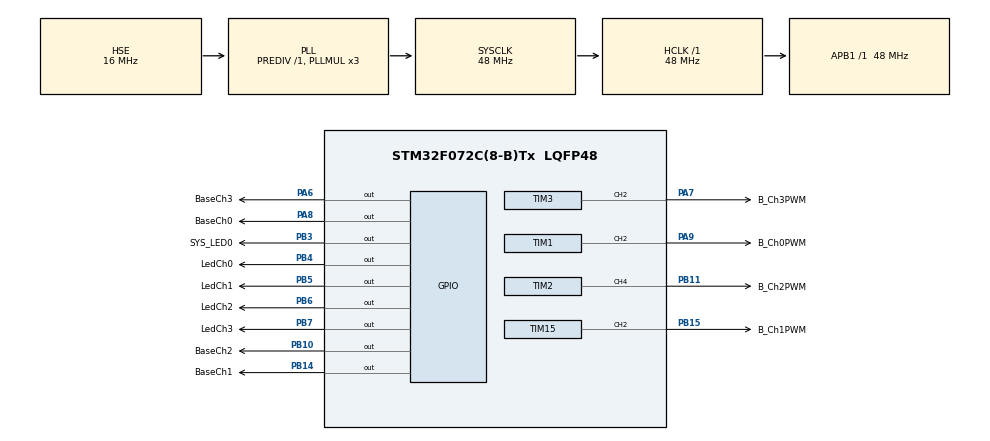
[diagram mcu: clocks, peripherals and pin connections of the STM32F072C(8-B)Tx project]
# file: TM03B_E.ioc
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Mcu.Family=STM32F0
Mcu.Name=STM32F072C(8-B)Tx
Mcu.Package=LQFP48
NVIC.TIM15_IRQn=true\:0\:0\:false\:false\:true\:true
NVIC.TIM1_BRK_UP_TRG_COM_IRQn=true\:0\:0\:false\:false\:true\:true
NVIC.TIM1_CC_IRQn=true\:0\:0\:false\:false\:true\:true
NVIC.TIM2_IRQn=true\:0\:0\:false\:false\:true\:true
NVIC.TIM3_IRQn=true\:0\:0\:false\:false\:true\:true
NVIC.TIM7_IRQn=true\:1\:0\:true\:false\:true\:true
PA13.Mode=Serial_Wire
PA13.Signal=SYS_SWDIO
PA14.Mode=Serial_Wire
PA14.Signal=SYS_SWCLK
PA6.GPIO_Label=BaseCh3
PA6.Signal=GPIO_Output
PA7.GPIO_Label=B_Ch3PWM
PA7.Signal=S_TIM3_CH2
PA8.GPIO_Label=BaseCh0
PA8.Signal=GPIO_Output
PA9.GPIO_Label=B_Ch0PWM
PA9.Signal=S_TIM1_CH2
PB10.GPIO_Label=BaseCh2
PB10.Signal=GPIO_Output
PB11.GPIO_Label=B_Ch2PWM
PB11.Signal=S_TIM2_CH4
PB14.GPIO_Label=BaseCh1
PB14.Signal=GPIO_Output
PB15.GPIO_Label=B_Ch1PWM
PB15.Signal=S_TIM15_CH2
PB3.GPIO_Label=SYS_LED0
PB3.Signal=GPIO_Output
PB4.GPIO_Label=LedCh0
PB4.PinState=GPIO_PIN_SET
PB4.Signal=GPIO_Output
PB5.GPIO_Label=LedCh1
PB5.PinState=GPIO_PIN_SET
PB5.Signal=GPIO_Output
PB6.GPIO_Label=LedCh2
PB6.PinState=GPIO_PIN_SET
PB6.Signal=GPIO_Output
PB7.GPIO_Label=LedCh3
PB7.PinState=GPIO_PIN_SET
PB7.Signal=GPIO_Output
PF0-OSC_IN.Mode=HSE-External-Oscillator
PF0-OSC_IN.Signal=RCC_OSC_IN
PF1-OSC_OUT.Mode=HSE-External-Oscillator
PF1-OSC_OUT.Signal=RCC_OSC_OUT
ProjectManager.HeapSize=0x200
ProjectManager.StackSize=0x400
ProjectManager.TargetToolchain=MDK-ARM V5
RCC.AHBFreq_Value=48000000
RCC.APB1Freq_Value=48000000
RCC.APB1TimFreq_Value=48000000
RCC.HCLKFreq_Value=48000000
RCC.HSE_VALUE=16000000
RCC.PLLMUL=RCC_PLL_MUL3
RCC.PLLSourceVirtual=RCC_PLLSOURCE_HSE
RCC.SYSCLKFreq_VALUE=48000000
RCC.SYSCLKSource=RCC_SYSCLKSOURCE_PLLCLK
SH.S_TIM15_CH2.0=TIM15_CH2,PWM Generation2 CH2
SH.S_TIM1_CH2.0=TIM1_CH2,PWM Generation2 CH2
SH.S_TIM2_CH4.0=TIM2_CH4,PWM Generation4 CH4
SH.S_TIM3_CH2.0=TIM3_CH2,PWM Generation2 CH2
TIM1.AutoReloadPreload=TIM_AUTORELOAD_PRELOAD_ENABLE
TIM1.Channel-PWM\ Generation2\ CH2=TIM_CHANNEL_2
TIM1.OCPolarity_2=TIM_OCPOLARITY_LOW
TIM1.Period=383
TIM1.Prescaler=0
TIM1.Pulse-PWM\ Generation2\ CH2=191
TIM1.RepetitionCounter=0
TIM15.AutoReloadPreload=TIM_AUTORELOAD_PRELOAD_ENABLE
TIM15.Channel-PWM\ Generation2\ CH2=TIM_CHANNEL_2
TIM15.OCPolarity_2=TIM_OCPOLARITY_LOW
TIM15.Period=383
TIM15.Pulse-PWM\ Generation2\ CH2=191
TIM2.AutoReloadPreload=TIM_AUTORELOAD_PRELOAD_ENABLE
TIM2.Channel-PWM\ Generation4\ CH4=TIM_CHANNEL_4
TIM2.OCPolarity_4=TIM_OCPOLARITY_LOW
TIM2.Period=383
TIM2.Pulse-PWM\ Generation4\ CH4=191
TIM3.AutoReloadPreload=TIM_AUTORELOAD_PRELOAD_ENABLE
TIM3.Channel-PWM\ Generation2\ CH2=TIM_CHANNEL_2
TIM3.OCPolarity_2=TIM_OCPOLARITY_LOW
TIM3.Period=383
TIM3.Pulse-PWM\ Generation2\ CH2=191
TIM7.Period=249
TIM7.Prescaler=47999
VP_TIM1_VS_ClockSourceINT.Mode=Internal
VP_TIM7_VS_ClockSourceINT.Mode=Enable_Timer
board=TM03B_E

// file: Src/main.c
/**
  ******************************************************************************
  * File Name          : main.c
  * Description        : Main program body
  ******************************************************************************
  ** This notice applies to any and all portions of this file
  * that are not between comment pairs USER CODE BEGIN and
  * USER CODE END. Other portions of this file, whether
  * inserted by the user or by software development tools
  * are owned by their respective copyright owners.
  *
  * COPYRIGHT(c) 2017 STMicroelectronics
  *
  * Redistribution and use in source and binary forms, with or without modification,
  * are permitted provided that the following conditions are met:
  *   1. Redistributions of source code must retain the above copyright notice,
  *      this list of conditions and the following disclaimer.
  *   2. Redistributions in binary form must reproduce the above copyright notice,
  *      this list of conditions and the following disclaimer in the documentation
  *      and/or other materials provided with the distribution.
  *   3. Neither the name of STMicroelectronics nor the names of its contributors
  *      may be used to endorse or promote products derived from this software
  *      without specific prior written permission.
  *
  * THIS SOFTWARE IS PROVIDED BY THE COPYRIGHT HOLDERS AND CONTRIBUTORS "AS IS"
  * AND ANY EXPRESS OR IMPLIED WARRANTIES, INCLUDING, BUT NOT LIMITED TO, THE
  * IMPLIED WARRANTIES OF MERCHANTABILITY AND FITNESS FOR A PARTICULAR PURPOSE ARE
  * DISCLAIMED. IN NO EVENT SHALL THE COPYRIGHT HOLDER OR CONTRIBUTORS BE LIABLE
  * FOR ANY DIRECT, INDIRECT, INCIDENTAL, SPECIAL, EXEMPLARY, OR CONSEQUENTIAL
  * DAMAGES (INCLUDING, BUT NOT LIMITED TO, PROCUREMENT OF SUBSTITUTE GOODS OR
  * SERVICES; LOSS OF USE, DATA, OR PROFITS; OR BUSINESS INTERRUPTION) HOWEVER
  * CAUSED AND ON ANY THEORY OF LIABILITY, WHETHER IN CONTRACT, STRICT LIABILITY,
  * OR TORT (INCLUDING NEGLIGENCE OR OTHERWISE) ARISING IN ANY WAY OUT OF THE USE
  * OF THIS SOFTWARE, EVEN IF ADVISED OF THE POSSIBILITY OF SUCH DAMAGE.
  *
  ******************************************************************************
  */
#include "main.h"
#include "stm32f0xx_hal.h"
#include "tim.h"
#include "gpio.h"

/* USER CODE BEGIN Includes */
#include "base.h"
/* USER CODE END Includes */

/* USER CODE BEGIN PV */
/* Private variables ---------------------------------------------------------*/

/* USER CODE END PV */

void SystemClock_Config(void);

/* USER CODE BEGIN PFP */
/* Private function prototypes -----------------------------------------------*/

/* USER CODE END PFP */

/* USER CODE BEGIN 0 */
extern uint8_t finish;

/* USER CODE END 0 */

int main(void)
{

  /* MCU Configuration----------------------------------------------------------*/

  /* Reset of all peripherals, Initializes the Flash interface and the Systick. */
  HAL_Init();

  /* Configure the system clock */
  SystemClock_Config();

  /* Initialize all configured peripherals */
  MX_GPIO_Init();
  MX_TIM1_Init();
  MX_TIM15_Init();
  MX_TIM2_Init();
  MX_TIM3_Init();
  MX_TIM7_Init();

  /* USER CODE BEGIN 2 */

	HAL_GPIO_WritePin(SYS_LED0_GPIO_Port, SYS_LED0_Pin, GPIO_PIN_RESET);
	Base_Para_Init();
	HAL_TIM_Base_Start_IT(&htim7);
//	Base_Ch0_Start();
  /* USER CODE END 2 */

  /* Infinite loop */
  /* USER CODE BEGIN WHILE */
  while (1)
  {
		Base_Process();

//		if(finish)
//		{
//			finish = 0;
//			HAL_TIM_PWM_Stop(&htim1,TIM_CHANNEL_2);
//		}
  /* USER CODE END WHILE */

  }

}

/** System Clock Configuration
*/
void SystemClock_Config(void)
{

  RCC_OscInitTypeDef RCC_OscInitStruct;
  RCC_ClkInitTypeDef RCC_ClkInitStruct;

    /**Initializes the CPU, AHB and APB busses clocks
    */
  RCC_OscInitStruct.OscillatorType = RCC_OSCILLATORTYPE_HSE;
  RCC_OscInitStruct.HSEState = RCC_HSE_ON;
  RCC_OscInitStruct.HSIState = RCC_HSI_ON;
  RCC_OscInitStruct.PLL.PLLState = RCC_PLL_ON;
  RCC_OscInitStruct.PLL.PLLSource = RCC_PLLSOURCE_HSE;
  RCC_OscInitStruct.PLL.PLLMUL = RCC_PLL_MUL3;
  RCC_OscInitStruct.PLL.PREDIV = RCC_PREDIV_DIV1;
  if (HAL_RCC_OscConfig(&RCC_OscInitStruct) != HAL_OK)
  {
    _Error_Handler(__FILE__, __LINE__);
  }

    /**Initializes the CPU, AHB and APB busses clocks
    */
  RCC_ClkInitStruct.ClockType = RCC_CLOCKTYPE_HCLK|RCC_CLOCKTYPE_SYSCLK
                              |RCC_CLOCKTYPE_PCLK1;
  RCC_ClkInitStruct.SYSCLKSource = RCC_SYSCLKSOURCE_PLLCLK;
  RCC_ClkInitStruct.AHBCLKDivider = RCC_SYSCLK_DIV1;
  RCC_ClkInitStruct.APB1CLKDivider = RCC_HCLK_DIV1;

  if (HAL_RCC_ClockConfig(&RCC_ClkInitStruct, FLASH_LATENCY_1) != HAL_OK)
  {
    _Error_Handler(__FILE__, __LINE__);
  }

    /**Configure the Systick interrupt time
    */
  HAL_SYSTICK_Config(HAL_RCC_GetHCLKFreq()/1000);

    /**Configure the Systick
    */
  HAL_SYSTICK_CLKSourceConfig(SYSTICK_CLKSOURCE_HCLK);

  /* SysTick_IRQn interrupt configuration */
  HAL_NVIC_SetPriority(SysTick_IRQn, 0, 0);
}

void _Error_Handler(char * file, int line)
{
  while(1)
  {
  }
}

/************************ (C) COPYRIGHT STMicroelectronics *****END OF FILE****/
